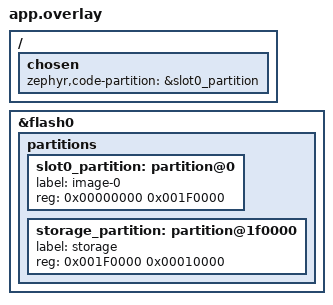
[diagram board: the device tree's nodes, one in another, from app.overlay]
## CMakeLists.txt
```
cmake_minimum_required(VERSION 3.20.0)

get_filename_component(REPO_DIR "${CMAKE_CURRENT_LIST_DIR}/../.." ABSOLUTE)
set(BOARD_ROOT   ${REPO_DIR})
set(SOC_ROOT     ${REPO_DIR})
set(DTS_ROOT     ${REPO_DIR})
set(KCONFIG_ROOT ${REPO_DIR}/Kconfig)
list(APPEND ZEPHYR_EXTRA_MODULES ${REPO_DIR})

find_package(Zephyr REQUIRED HINTS $ENV{ZEPHYR_BASE})
project(rt584_hello_bare)

target_sources(app PRIVATE src/main.c)
```

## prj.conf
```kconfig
# Standalone Zephyr image — no MCUboot, links at flash base (0x10000000 on rt584).
CONFIG_SERIAL=y
CONFIG_CONSOLE=y
CONFIG_UART_CONSOLE=y
CONFIG_PRINTK=y
```

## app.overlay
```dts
/*
 * Standalone build — image lives at the start of flash (0x10000000).
 * Replace partitions: a single slot0 covering the whole flash, used as
 * code-partition. No MCUboot.
 */

/delete-node/ &boot_partition;
/delete-node/ &slot0_partition;
/delete-node/ &slot1_partition;
/delete-node/ &storage_partition;
/delete-node/ &factory_partition;

&flash0 {
    partitions {
        slot0_partition: partition@0 {
            label = "image-0";
            reg = <0x00000000 0x001F0000>;  /* 1984 KB, almost whole 2 MB */
        };

        storage_partition: partition@1f0000 {
            label = "storage";
            reg = <0x001F0000 0x00010000>;  /* 64 KB */
        };
    };
};

/ {
    chosen {
        zephyr,code-partition = &slot0_partition;
    };
};
```

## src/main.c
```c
#include <zephyr/kernel.h>

int main(void)
{
    printk("Hello World! RT584-EVB BARE\n");
    while (1) {
        k_msleep(1000);
        printk("tick\n");
    }
    return 0;
}
```
